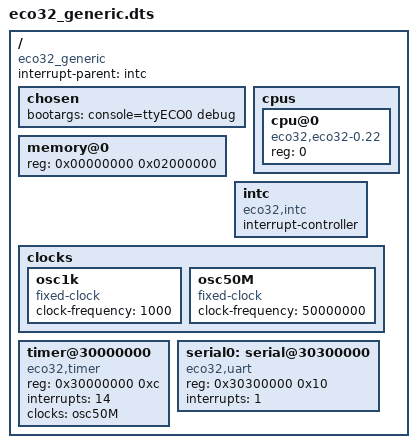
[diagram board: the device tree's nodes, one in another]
/dts-v1/;
/ {
	compatible = "eco32_generic";
	#address-cells = <1>;
	#size-cells = <1>;
	interrupt-parent = <&intc>;

	chosen {
		bootargs = "console=ttyECO0 debug";
	};

	cpus {
		#address-cells = <1>;
		#size-cells = <0>;

	     	cpu@0 {
			device_type = "cpu";
			compatible = "eco32,eco32-0.22";
			reg = <0>;
		};
	};

	memory@0 {
		device_type = "memory";
		reg = <0x00000000 0x02000000>;
	};

	intc: intc {
		compatible = "eco32,intc";
		#interrupt-cells = <1>;
		interrupt-controller;
	};

       clocks {
                #address-cells = <1>;
                #size-cells = <1>;
                ranges;

                osc1k: osc1k {
                        #clock-cells = <0>;
                        compatible = "fixed-clock";
                        clock-frequency = <1000>;
                };

                osc50M: osc50M {
                        #clock-cells = <0>;
                        compatible = "fixed-clock";
                        clock-frequency = <50000000>;
                };
	};

	timer@30000000 {
		compatible = "eco32,timer";
		reg = <0x30000000 0xc>;
		interrupts = <14>;
		clocks = <&osc50M>;
	};

	serial0: serial@30300000 {
		compatible = "eco32,uart";
		reg = <0x30300000 0x10>;
		interrupts = <1>;
	};
};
